# RZT2H register map
Vendor: Renesas Electronics Corporation; Series: RZT; File version: 1.00.00
CPU: other r0p0, little endian, MPU, no FPU, VTOR, 4 interrupt priority bits, 624 interrupts
Registers are 32-bit, read-write, reset 0x0 unless marked. A register's access mark holds for its fields unless they carry their own. Offsets are from the block's base; [hi:lo] are bit positions; 'fields as' and 'values as' point back to an identical list; <NAME> marks a mode.

## TSU_B0 — Temperature Sensor Unit
Base 0x80086000
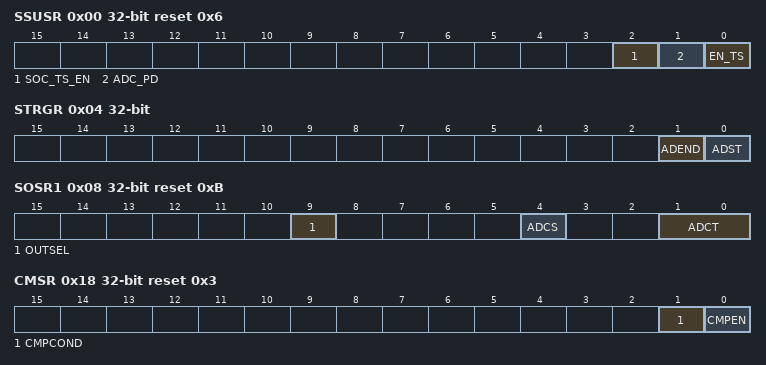
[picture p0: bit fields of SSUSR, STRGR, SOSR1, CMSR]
0x00 SSUSR reset 0x6 — Sensor Suspend Register
  [2] SOC_TS_EN
    0=Disable; 1=Enable
  [1] ADC_PD
    0=Normal operation; 1=Power down
  [0] EN_TS
    0=Temperature Sensor power down; 1=Temperature Sensor normal operation
0x04 STRGR wo (reset mask 0xFFFFFFFC) — Sensor Trigger Register
  [1] ADEND
    0=No effect; 1=conversion ends
  [0] ADST
    0=No effect; 1=Conversion starts
0x08 SOSR1 reset 0xB — Sensor Operation Setting 1 Register
  [9] OUTSEL ro
    0=Latest read data; 1=Average data
  [4] ADCS
    0=Single scan mode; 1=Continuous scan mode
  [1:0] ADCT
    0=1; 1=2; 2=4; 3=8
0x10 SCRR ro — Sensor Code Read Register
  [11:0] OUT12BIT_TS
0x14 SSR ro — Sensor Status Register
  [0] CONV
    0=Conversion is completed. Single scan mode: AD conversion of the number of times needed for average data is completed. Continuous mode: AD conversion of the number of times needed for average data is completed after ADEND is asserted.; 1=Conversion is in progress. Set when ADST bit of Sensor Trigger Register is asserted.
0x18 CMSR reset 0x3 — Compare Mode Setting Register
  [1] CMPCOND
    0=Outside of the range Lower Limit (LLILM) > Code Data, or Code Data > Upper Limit (ULIM); 1=Inside of the range Lower Limit (LLILM) < Code Data < Upper Limit (ULIM)
  [0] CMPEN
    0=Disable; 1=Enable
0x1C LLSR — Lower Limit Setting Register
  [11:0] LLIM
0x20 ULSR — Upper Limit Setting Register
  [11:0] ULIM
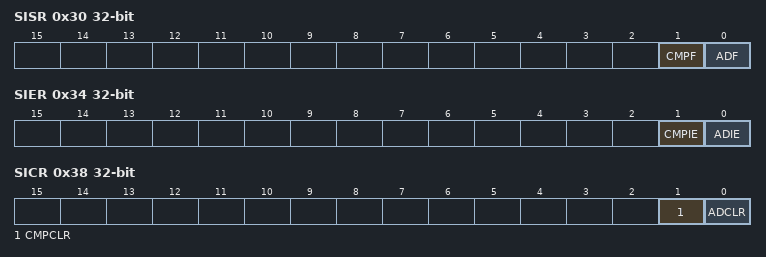
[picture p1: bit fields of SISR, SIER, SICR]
0x30 SISR ro — Sensor Interrupt Status Register
  [1] CMPF — Compare Result Flag
    0=Not matched; 1=Matched
  [0] ADF — AD Conversion Complete Flag
    0=Not completed; 1=Completed
0x34 SIER — Sensor Interrupt Enable Register
  [1] CMPIE
    0=Disable; 1=Enable
  [0] ADIE
    0=Disable; 1=Enable
0x38 SICR wo (reset mask 0xFFFFFFFC) — Sensor Interrupt Clear Register
  [1] CMPCLR
    0=No effect; 1=Interrupt is cleared
  [0] ADCLR
    0=No effect; 1=Interrupt is cleared

## POEG1 — GPT Port Output Enable 1
Base 0x80087000
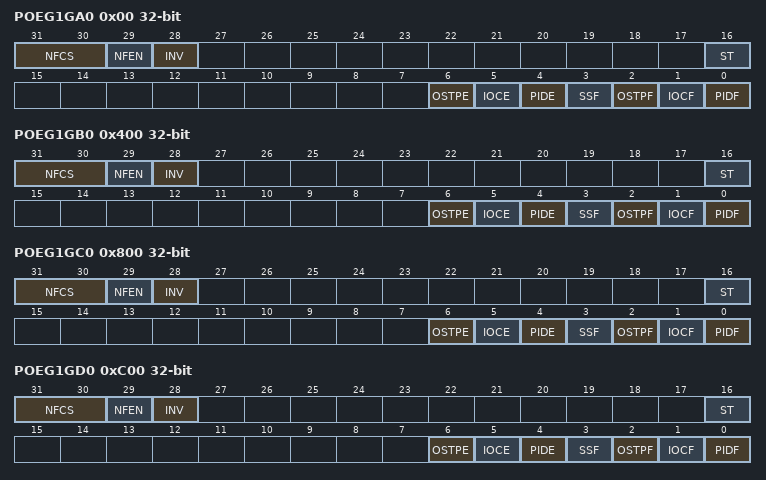
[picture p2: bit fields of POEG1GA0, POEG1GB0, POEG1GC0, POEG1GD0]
0x00 POEG1GA0 — POEG1 Group A Setting Register 0
  [31:30] NFCS — Noise filter Clock Select
    0=Samples the input level of GTETRGn pin three times per PCLKL clock; 1=Samples the input level of GTETRGn pin three times per PCLKL/8 clock; 2=Samples the input level of GTETRGn pin three times per PCLKL/32 clock; 3=Samples the input level of GTETRGn pin three times per PCLKL/128 clock
  [29] NFEN — Noise filter Enable
    0=Digital noise filter on the GTETRGn pin is disabled; 1=Digital noise filter on the GTETRGn pin is enabled
  [28] INV — GTETRGn Input Inverting
    0=Input on the GTETRGn pin is not inverted; 1=Input on the GTETRGn pin is inverted
  [16] ST ro — GTETRGn Input Status Flag
    0=GTETRGn input after filtering was 0; 1=GTETRGn input after filtering was 1
  [6] OSTPE — Enable Stopping Output on Stopping of Oscillation
    0=Detection of stopping of oscillation is disabled; 1=Detection of stopping of oscillation is enabled
  [5] IOCE — GPT Output Stop Request Enable
    0=Detection of stopping of output from the GPT is disabled; 1=Detection of stopping of output from the GPT is enabled
  [4] PIDE — Port Input Detection Enable
    0=Detection of input levels on the corresponding GTETRGn pin is disabled; 1=Detection of input levels on the corresponding GTETRGn pin is enabled
  [3] SSF — Software Stop Flag
    0=Software has not stopped output; 1=Software has stopped output
  [2] OSTPF — Oscillation Stop Detection Flag
    0=Stopping of oscillation was not detected; 1=Stopping of oscillation was detected
  [1] IOCF — GPT Output Stop Request Detection Flag
    0=Stopping of GPT output was not detected; 1=Stopping of GPT output was detected
  [0] PIDF — Port Input Detection Flag
    0=The selected input level was not detected on the GTETRGn pin; 1=The selected input level was detected on the GTETRGn pin
0x400 POEG1GB0 — POEG1 Group B Setting Register 0
  fields as POEG1GA0
0x800 POEG1GC0 — POEG1 Group C Setting Register 0
  fields as POEG1GA0
0xC00 POEG1GD0 — POEG1 Group D Setting Register 0
  fields as POEG1GA0

## POEG2 — GPT Port Output Enable 2
Base 0x8100A000
Registers as POEG1 (with POEG1 read as POEG2).

## Notices in the file
Copyright (c) 2020 - 2025 Renesas Electronics Corporation and/or its affiliates
SPDX-License-Identifier: BSD-3-Clause
